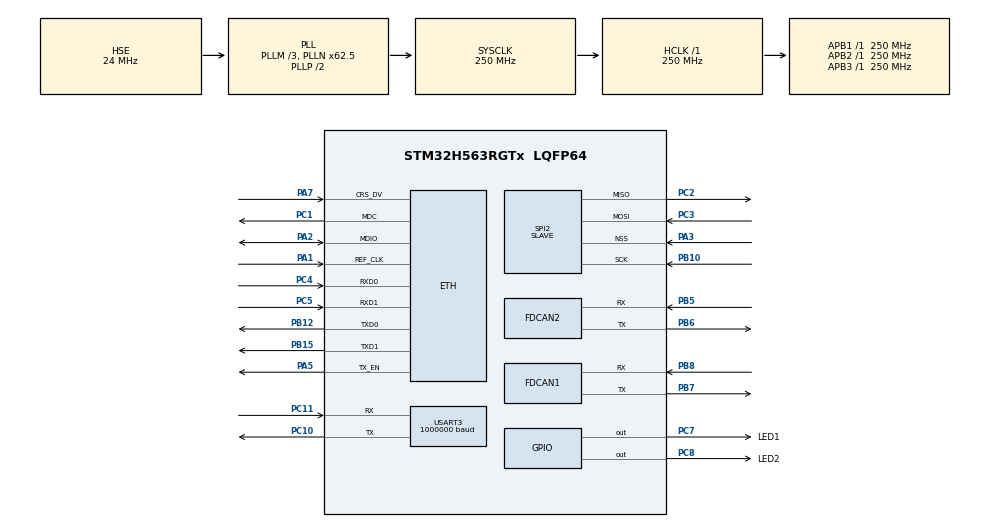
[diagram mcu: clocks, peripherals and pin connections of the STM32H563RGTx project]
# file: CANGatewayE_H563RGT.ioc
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BOOTPATH.BootPathName=LEGACY
BOOTPATH.UserSelectedBootPath=LEGACY
CORTEX_M33_NS.userName=CORTEX_M33
ETH.MediaInterface=HAL_ETH_RMII_MODE
FDCAN1.CalculateBaudRateNominal=1000000
FDCAN1.CalculateTimeBitNominal=1000
FDCAN1.CalculateTimeQuantumNominal=83.33333333333333
FDCAN1.ExtFiltersNbr=1
FDCAN1.NominalPrescaler=2
FDCAN1.NominalTimeSeg1=10
FDCAN1.NominalTimeSeg2=1
FDCAN1.StdFiltersNbr=1
FDCAN2.CalculateBaudRateNominal=1000000
FDCAN2.CalculateTimeBitNominal=1000
FDCAN2.CalculateTimeQuantumNominal=83.33333333333333
FDCAN2.ExtFiltersNbr=1
FDCAN2.NominalPrescaler=2
FDCAN2.NominalTimeSeg1=10
FDCAN2.NominalTimeSeg2=1
FDCAN2.StdFiltersNbr=1
Mcu.Family=STM32H5
Mcu.Name=STM32H563RGTx
Mcu.Package=LQFP64
NETXDUO.ETH_ON=1
NETXDUO.LAN_8742=1
NETXDUO.NX_APP_MEM_POOL_SIZE=1024*20
NETXDUO.NX_ENABLE_INTERFACE_CAPABILITY=true
NETXDUO.NX_ENABLE_TCP_KEEPALIVE=false
NETXDUO.NX_IP_FAST_TIMER_RATE=100
NETXDUO.NX_IP_PERIODIC_RATE=500
NETXDUO.NX_RETRANS_TIMER=100
NETXDUO.NX_TCP_KEEPALIVE_INITIAL=7200
NETXDUO.NX_TCP_KEEPALIVE_RETRY=75
NETXDUO.NetXDuo_Generate_Init_Code=true
NETXDUO.NetXDuo_Static_IP_address=192.168.40.20
NVIC.ETH_IRQn=true\:0\:0\:false\:false\:true\:false\:true\:true\:true
NVIC.FDCAN1_IT0_IRQn=true\:1\:0\:true\:false\:true\:false\:true\:true\:true
NVIC.FDCAN2_IT0_IRQn=true\:0\:0\:false\:false\:true\:false\:true\:true\:true
NVIC.PriorityGroup=NVIC_PRIORITYGROUP_4
NVIC.TIM6_IRQn=true\:15\:0\:false\:false\:true\:false\:false\:true\:true
NVIC.TimeBase=TIM6_IRQn
NVIC.TimeBaseIP=TIM6
NetXDuo.BSP.number=1
NetXDuo0.BSP.STBoard=false
NetXDuo0.BSP.api=BSP_COMPONENT_DRIVER
NetXDuo0.BSP.component=lan8742
NetXDuo0.BSP.instance=lan8742
NetXDuo0.BSP.name=LAN_Component
NetXDuo0.BSP.semaphore=SEMA_lan8742
NetXDuo0.BSP.solution=lan8742
PA1.GPIO_Speed_Default_HIGH=GPIO_SPEED_FREQ_VERY_HIGH
PA1.Mode=RMII
PA1.Signal=ETH_REF_CLK
PA13(JTMS/SWDIO).Signal=DEBUG_JTMS-SWDIO
PA14(JTCK/SWCLK).Signal=DEBUG_JTCK-SWCLK
PA15(JTDI).Signal=SPI3_NSS
PA2.GPIO_Speed_Default_HIGH=GPIO_SPEED_FREQ_VERY_HIGH
PA2.Mode=RMII
PA2.Signal=ETH_MDIO
PA3.Mode=NSS_Signal_Hard_Input
PA3.Signal=SPI2_NSS
PA5.GPIO_Speed_Default_HIGH=GPIO_SPEED_FREQ_VERY_HIGH
PA5.Mode=RMII
PA5.Signal=ETH_TX_EN
PA7.GPIO_Speed_Default_HIGH=GPIO_SPEED_FREQ_VERY_HIGH
PA7.Mode=RMII
PA7.Signal=ETH_CRS_DV
PB10.Mode=Full_Duplex_Slave
PB10.Signal=SPI2_SCK
PB12.GPIO_Speed_Default_HIGH=GPIO_SPEED_FREQ_VERY_HIGH
PB12.Mode=RMII
PB12.Signal=ETH_TXD0
PB15.GPIO_Speed_Default_HIGH=GPIO_SPEED_FREQ_VERY_HIGH
PB15.Mode=RMII
PB15.Signal=ETH_TXD1
PB5.Mode=FDCAN_Activate
PB5.Signal=FDCAN2_RX
PB6.GPIO_Speed=GPIO_SPEED_FREQ_HIGH
PB6.Mode=FDCAN_Activate
PB6.Signal=FDCAN2_TX
PB7.GPIO_Speed=GPIO_SPEED_FREQ_HIGH
PB7.Mode=FDCAN_Activate
PB7.Signal=FDCAN1_TX
PB8.GPIO_Speed=GPIO_SPEED_FREQ_HIGH
PB8.Mode=FDCAN_Activate
PB8.Signal=FDCAN1_RX
PC1.GPIO_Speed_Default_HIGH=GPIO_SPEED_FREQ_VERY_HIGH
PC1.Mode=RMII
PC1.Signal=ETH_MDC
PC10.Mode=Asynchronous
PC10.Signal=USART3_TX
PC11.Mode=Asynchronous
PC11.Signal=USART3_RX
PC12.Signal=SPI3_MOSI
PC2.Mode=Full_Duplex_Slave
PC2.Signal=SPI2_MISO
PC3.Mode=Full_Duplex_Slave
PC3.Signal=SPI2_MOSI
PC4.GPIO_Speed_Default_HIGH=GPIO_SPEED_FREQ_VERY_HIGH
PC4.Mode=RMII
PC4.Signal=ETH_RXD0
PC5.GPIO_Speed_Default_HIGH=GPIO_SPEED_FREQ_VERY_HIGH
PC5.Mode=RMII
PC5.Signal=ETH_RXD1
PC7.GPIO_Label=LED1
PC7.Signal=GPIO_Output
PC8.GPIO_Label=LED2
PC8.Signal=GPIO_Output
PH0-OSC_IN(PH0).Mode=HSE-External-Oscillator
PH0-OSC_IN(PH0).Signal=RCC_OSC_IN
PH1-OSC_OUT(PH1).Mode=HSE-External-Oscillator
PH1-OSC_OUT(PH1).Signal=RCC_OSC_OUT
ProjectManager.HeapSize=0x200
ProjectManager.StackSize=0x400
ProjectManager.TargetToolchain=STM32CubeIDE
RCC.ADCFreq_Value=250000000
RCC.AHBFreq_Value=250000000
RCC.APB1Freq_Value=250000000
RCC.APB1TimFreq_Value=250000000
RCC.APB2Freq_Value=250000000
RCC.APB2TimFreq_Value=250000000
RCC.APB3Freq_Value=250000000
RCC.CSI_VALUE=4000000
RCC.CortexFreq_Value=250000000
RCC.EPOD_VALUE=24000000
RCC.HCLKFreq_Value=250000000
RCC.HSE_VALUE=24000000
RCC.HSI48_VALUE=48000000
RCC.HSI_VALUE=64000000
RCC.LSE_VALUE=32768
RCC.LSIRC_VALUE=32000
RCC.PLL2FRACN=0
RCC.PLL3FRACN=0
RCC.PLLFRACN=4096
RCC.PLLM=3
RCC.PLLN=62
RCC.PLLSourceVirtual=RCC_PLL1_SOURCE_HSE
RCC.SYSCLKFreq_VALUE=250000000
RCC.SYSCLKSource=RCC_SYSCLKSOURCE_PLLCLK
RCC.USBFreq_Value=48000000
RCC.VCOOutputFreq_Value=500000000
SPI2.Direction=SPI_DIRECTION_2LINES
SPI2.Mode=SPI_MODE_SLAVE
SPI2.VirtualNSS=VM_NSSHARD
SPI2.VirtualType=VM_SLAVE
THREADX.TX_APP_MEM_POOL_SIZE=1024*40
THREADX.TX_TIMER_TICKS_PER_SECOND=1000
USART3.BaudRate=1000000
USART3.VirtualMode=VM_ASYNC
VP_BOOTPATH_VS_BOOTPATH.Mode=BP_Activate
VP_ICACHE_VS_ICACHE.Mode=DefaultMode
VP_MEMORYMAP_VS_MEMORYMAP.Mode=CurAppReg
VP_NETXDUO_VS_EthernetOoPhyOoInterface.Mode=LAN8742_Phy_Interface
VP_NETXDUO_VS_NXOoCore.Mode=NX_Core
VP_NETXDUO_VS_NetworkOoInterface.Mode=Ethernet_Interface
VP_PWR_VS_DBSignals.Mode=DisableDeadBatterySignals
VP_PWR_VS_LPOM.Mode=PowerOptimisation
VP_PWR_VS_SECSignals.Mode=Security/Privilege
VP_SYS_VS_tim6.Mode=TIM6
VP_THREADX_VS_RTOSJjThreadXJjCoreJjDefault.Mode=Core_Default
board=custom

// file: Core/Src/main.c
/* USER CODE BEGIN Header */
/**
  ******************************************************************************
  * @file           : main.c
  * @brief          : Main program body
  ******************************************************************************
  * @attention
  *
  * Copyright (c) 2024 STMicroelectronics.
  * All rights reserved.
  *
  * This software is licensed under terms that can be found in the LICENSE file
  * in the root directory of this software component.
  * If no LICENSE file comes with this software, it is provided AS-IS.
  *
  ******************************************************************************
  */
/* USER CODE END Header */
#include "app_threadx.h"
#include "main.h"
#include "eth.h"
#include "fdcan.h"
#include "icache.h"
#include "memorymap.h"
#include "spi.h"
#include "usart.h"
#include "gpio.h"

/* USER CODE BEGIN Includes */
#include <stdio.h>
/* USER CODE END Includes */

void SystemClock_Config(void);

/* USER CODE BEGIN 0 */
int __io_putchar(int ch) {
    HAL_UART_Transmit(&huart3, (uint8_t *)&ch, 1, 10);
    return 0;
}
/* USER CODE END 0 */

int main(void)
{

  /* MCU Configuration--------------------------------------------------------*/

  /* Reset of all peripherals, Initializes the Flash interface and the Systick. */
  HAL_Init();

  /* Configure the system clock */
  SystemClock_Config();

  /* Initialize all configured peripherals */
  MX_GPIO_Init();
  MX_ETH_Init();
  MX_FDCAN1_Init();
  MX_FDCAN2_Init();
  MX_ICACHE_Init();
  MX_USART3_UART_Init();
  MX_SPI2_Init();
  /* USER CODE BEGIN 2 */
  setbuf(stdout, NULL);
  HAL_Delay(5000);
  /* USER CODE END 2 */

  MX_ThreadX_Init();

  /* We should never get here as control is now taken by the scheduler */
  /* Infinite loop */
  while (1)
  {

  }
}

void SystemClock_Config(void)
{
  RCC_OscInitTypeDef RCC_OscInitStruct = {0};
  RCC_ClkInitTypeDef RCC_ClkInitStruct = {0};

  /** Configure the main internal regulator output voltage
  */
  __HAL_PWR_VOLTAGESCALING_CONFIG(PWR_REGULATOR_VOLTAGE_SCALE0);

  while(!__HAL_PWR_GET_FLAG(PWR_FLAG_VOSRDY)) {}

  /** Initializes the RCC Oscillators according to the specified parameters
  * in the RCC_OscInitTypeDef structure.
  */
  RCC_OscInitStruct.OscillatorType = RCC_OSCILLATORTYPE_HSE;
  RCC_OscInitStruct.HSEState = RCC_HSE_ON;
  RCC_OscInitStruct.PLL.PLLState = RCC_PLL_ON;
  RCC_OscInitStruct.PLL.PLLSource = RCC_PLL1_SOURCE_HSE;
  RCC_OscInitStruct.PLL.PLLM = 3;
  RCC_OscInitStruct.PLL.PLLN = 62;
  RCC_OscInitStruct.PLL.PLLP = 2;
  RCC_OscInitStruct.PLL.PLLQ = 2;
  RCC_OscInitStruct.PLL.PLLR = 2;
  RCC_OscInitStruct.PLL.PLLRGE = RCC_PLL1_VCIRANGE_3;
  RCC_OscInitStruct.PLL.PLLVCOSEL = RCC_PLL1_VCORANGE_WIDE;
  RCC_OscInitStruct.PLL.PLLFRACN = 4096;
  if (HAL_RCC_OscConfig(&RCC_OscInitStruct) != HAL_OK)
  {
    Error_Handler();
  }

  /** Initializes the CPU, AHB and APB buses clocks
  */
  RCC_ClkInitStruct.ClockType = RCC_CLOCKTYPE_HCLK|RCC_CLOCKTYPE_SYSCLK
                              |RCC_CLOCKTYPE_PCLK1|RCC_CLOCKTYPE_PCLK2
                              |RCC_CLOCKTYPE_PCLK3;
  RCC_ClkInitStruct.SYSCLKSource = RCC_SYSCLKSOURCE_PLLCLK;
  RCC_ClkInitStruct.AHBCLKDivider = RCC_SYSCLK_DIV1;
  RCC_ClkInitStruct.APB1CLKDivider = RCC_HCLK_DIV1;
  RCC_ClkInitStruct.APB2CLKDivider = RCC_HCLK_DIV1;
  RCC_ClkInitStruct.APB3CLKDivider = RCC_HCLK_DIV1;

  if (HAL_RCC_ClockConfig(&RCC_ClkInitStruct, FLASH_LATENCY_5) != HAL_OK)
  {
    Error_Handler();
  }
}

void HAL_TIM_PeriodElapsedCallback(TIM_HandleTypeDef *htim)
{
  if (htim->Instance == TIM6) {
    HAL_IncTick();
  }
}

void Error_Handler(void)
{
  /* USER CODE BEGIN Error_Handler_Debug */
  /* User can add his own implementation to report the HAL error return state */
//  __disable_irq();
  while (1)
  {
	  HAL_GPIO_TogglePin(LED1_GPIO_Port, LED1_Pin);
    HAL_Delay(100);
  }
  /* USER CODE END Error_Handler_Debug */
}
